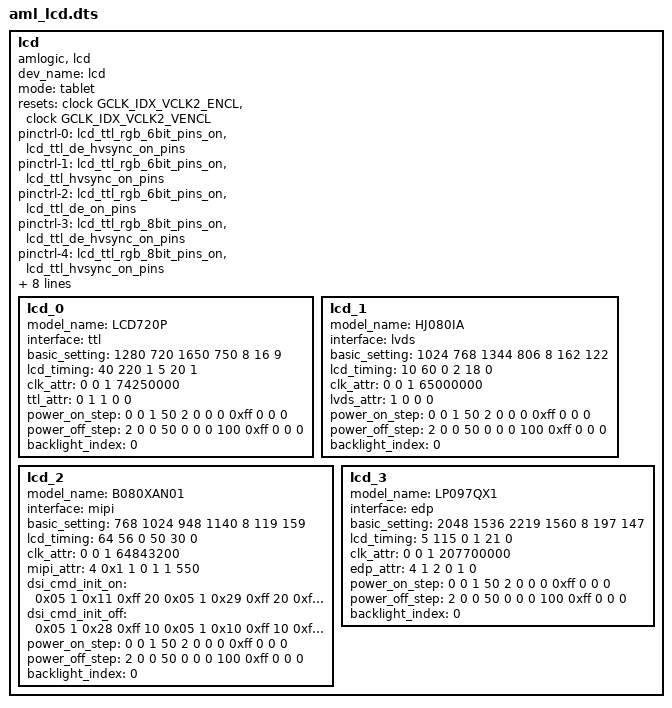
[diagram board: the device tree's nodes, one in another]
/*
 * drivers/amlogic/media/vout/lcd/lcd_tablet/aml_lcd.dts
 *
 * Copyright (C) 2017 Amlogic, Inc. All rights reserved.
 *
 * This program is free software; you can redistribute it and/or modify
 * it under the terms of the GNU General Public License as published by
 * the Free Software Foundation; either version 2 of the License, or
 * (at your option) any later version.
 *
 * This program is distributed in the hope that it will be useful, but WITHOUT
 * ANY WARRANTY; without even the implied warranty of MERCHANTABILITY or
 * FITNESS FOR A PARTICULAR PURPOSE.  See the GNU General Public License for
 * more details.
 *
 */

lcd{
	compatible = "amlogic, lcd";
	dev_name = "lcd";
	mode = "tablet";
	status = "okay";
	resets = <&clock GCLK_IDX_VCLK2_ENCL &clock GCLK_IDX_VCLK2_VENCL>;
	reset-names = "encl","vencl";
	pinctrl-names = "ttl_6bit_hvsync_de_on","ttl_6bit_hvsync_on",
		"ttl_6bit_de_on","ttl_8bit_hvsync_de_on",
		"ttl_8bit_hvsync_on","ttl_8bit_de_on",
		"ttl_6bit_hvsync_de_off","ttl_8bit_hvsync_de_off";
	pinctrl-0 = <&lcd_ttl_rgb_6bit_pins_on &lcd_ttl_de_hvsync_on_pins>;
	pinctrl-1 = <&lcd_ttl_rgb_6bit_pins_on &lcd_ttl_hvsync_on_pins>;
	pinctrl-2 = <&lcd_ttl_rgb_6bit_pins_on &lcd_ttl_de_on_pins>;
	pinctrl-3 = <&lcd_ttl_rgb_8bit_pins_on &lcd_ttl_de_hvsync_on_pins>;
	pinctrl-4 = <&lcd_ttl_rgb_8bit_pins_on &lcd_ttl_hvsync_on_pins>;
	pinctrl-5 = <&lcd_ttl_rgb_8bit_pins_on &lcd_ttl_de_on_pins>;
	pinctrl-6 = <&lcd_ttl_rgb_6bit_pins_off &lcd_ttl_de_hvsync_off_pins>;
	pinctrl-7 = <&lcd_ttl_rgb_8bit_pins_off &lcd_ttl_de_hvsync_off_pins>;

	/* power type:(0=cpu_gpio, 1=pmu_gpio,
	 * 2=signal, 3=extern, 0xff=ending)
	 */
	/* power index:(point gpios_index, or extern_index, 0xff=invalid) */
	/* power value:(0=output low, 1=output high, 2=input) */
	/* power delay:(unit in ms) */
	lcd_cpu-gpios = <&gpio GPIOX_3 GPIO_ACTIVE_HIGH>;
	lcd_cpu_gpio_names = "GPIOX_3";

	lcd_0{
		model_name = "LCD720P";
		interface = "ttl"; /* lcd_interface(ttl, lvds, mipi, edp) */
		basic_setting = <1280 720 1650 750 8 16 9>;
			/* h_active, v_active, h_period, v_period, lcd_bits,
			 * screen_widht, screen_height
			 */
		lcd_timing = <40 220 1 5 20 1>;
			/* hs_width, hs_bp, hs_pol, vs_width, vs_bp, vs_pol */
		clk_attr = <0 0 1 74250000>;
			/* fr_adj_type(0=clock, 1=htotal, 2=vtotal),
			 * clk_ss_level, clk_auto_generate,
			 * pixel_clk(unit in Hz)
			 */
		ttl_attr = <0 1 1 0 0>;
			/* clk_pol, de_valid, hvsync_valid,
			 * rb_swap, bit_swap
			 */
		power_on_step = <0 0 1 50
				2 0 0 0
				0xff 0 0 0>; /* type, index, value, delay */
		power_off_step = <2 0 0 50
				0 0 0 100
				0xff 0 0 0>; /* type, index, value, delay */
		backlight_index = <0>;
	};

	lcd_1{
		model_name = "HJ080IA";
		interface = "lvds"; /* lcd_interface(ttl, lvds, mipi, edp) */
		basic_setting = <1024 768 1344 806 8 162 122>;
			/* h_active, v_active, h_period, v_period, lcd_bits,
			 *	screen_widht, screen_height
			 */
		lcd_timing = <10 60 0 2 18 0>;
			/* hs_width, hs_bp, hs_pol, vs_width, vs_bp, vs_pol */
		clk_attr = <0 0 1 65000000>;
			/* fr_adj_type(0=clock, 1=htotal, 2=vtotal),
			 * clk_ss_level, clk_auto_generate,
			 * pixel_clk(unit in Hz)
			 */
		lvds_attr = <1 0 0 0>;
			/* lvds_repack, dual_port, pn_swap, port_swap */
		power_on_step = <0 0 1 50
				2 0 0 0
				0xff 0 0 0>; /* type, index, value, delay */
		power_off_step = <2 0 0 50
				0 0 0 100
				0xff 0 0 0>; /* type, index, value, delay */
		backlight_index = <0>;
	};

	/* operation_mode:(bit[0] for init, bit[1] for display.
	 *0=video mode, 1=command mode)
	 */
	/* lp_clk_continuous:(0=disable, 1=enable) */
	/* transfer_switch:(0=auto, 1=standard, 2=slow) */
	/* clk_factor:(special adjust between pixel_clk
	 * & lanebyte_clk, default 0)
	 */
	/* mipi-dsi command:(data_type, num, data....).
	 *	data_type=0xff, num=0xff means ending
	 *			num<0xff means delay num(unit: ms)
	 */
	lcd_2{
		model_name = "B080XAN01";
		interface = "mipi"; /* lcd_interface(ttl, lvds, mipi, edp) */
		basic_setting = <768 1024 948 1140 8 119 159>;
			/* h_active, v_active, h_period, v_period, lcd_bits,
			 *	screen_widht, screen_height
			 */
		lcd_timing = <64 56 0 50 30 0>;
			/* hs_width, hs_bp, hs_pol, vs_width, vs_bp, vs_pol */
		clk_attr = <0 0 1 64843200>;
			/* fr_adj_type(0=clock, 1=htotal, 2=vtotal),
			 * clk_ss_level, clk_auto_generate,
			 * pixel_clk(unit in Hz)
			 */
		mipi_attr = <4 0x1 1 0 1 1 550>;
			/* lane_count, operation_mode, lp_clk_continuous,
			 * transfer_switch, factor_denominator,
			 * factor_numerator, dsi_bit_rate_max (MHz)
			 */
		dsi_cmd_init_on = <0x05 1 0x11 /* sleep out */
				0xff 20     /* delay 20ms */
				0x05 1 0x29 /* display on */
				0xff 20     /* delay 20ms */
				0xff 0xff>; /* ending flag */
		dsi_cmd_init_off = <0x05 1 0x28 /* display off */
				0xff 10     /* delay 10ms */
				0x05 1 0x10 /* sleep in */
				0xff 10     /* delay 10ms */
				0xff 0xff>; /* ending flag */
		power_on_step = <0 0 1 50
				2 0 0 0
				0xff 0 0 0>; /* type, index, value, delay */
		power_off_step = <2 0 0 50
				0 0 0 100
				0xff 0 0 0>; /* type, index, value, delay */
		backlight_index = <0>;
	};

	/* link_rate:(0=1.62G, 1=2.7G, 0xff=auto setting) */
	/* lane_count:(support 1,2,4, 0xff=auto setting) */
	/* link_vswing:(support level 0,1,2,3, 0xff=adaptive) */
	/* sync_clk_mode:(0=asyncronous clock,
	 * 1=synchronous clock. default 1)
	 */
	/* edid_timing_used:(0=no use, 1=use) */
	lcd_3{
		model_name = "LP097QX1";
		interface = "edp"; /* lcd_interface(ttl, lvds, mipi, edp) */
		basic_setting = <2048 1536 2219 1560 8 197 147>;
			/* h_active, v_active, h_period, v_period, lcd_bits,
			 *	screen_widht, screen_height
			 */
		lcd_timing = <5 115 0 1 21 0>;
			/* hs_width, hs_bp, hs_pol, vs_width, vs_bp, vs_pol */
		clk_attr = <0 0 1 207700000>;
			/* fr_adj_type(0=clock, 1=htotal, 2=vtotal),
			 * clk_ss_level, clk_auto_generate,
			 * pixel_clk(unit in Hz)
			 */
		edp_attr = <4 1 2 0 1 0>;
			/* max_lane_count, link_rate, lane_count, link_vswing,
			 *	sync_clk_mode, edid_timing_used
			 */
		power_on_step = <0 0 1 50
				2 0 0 0
				0xff 0 0 0>; /* type, index, value, delay */
		power_off_step = <2 0 0 50
				0 0 0 100
				0xff 0 0 0>; /* type, index, value, delay */
		backlight_index = <0>;
	};
};
